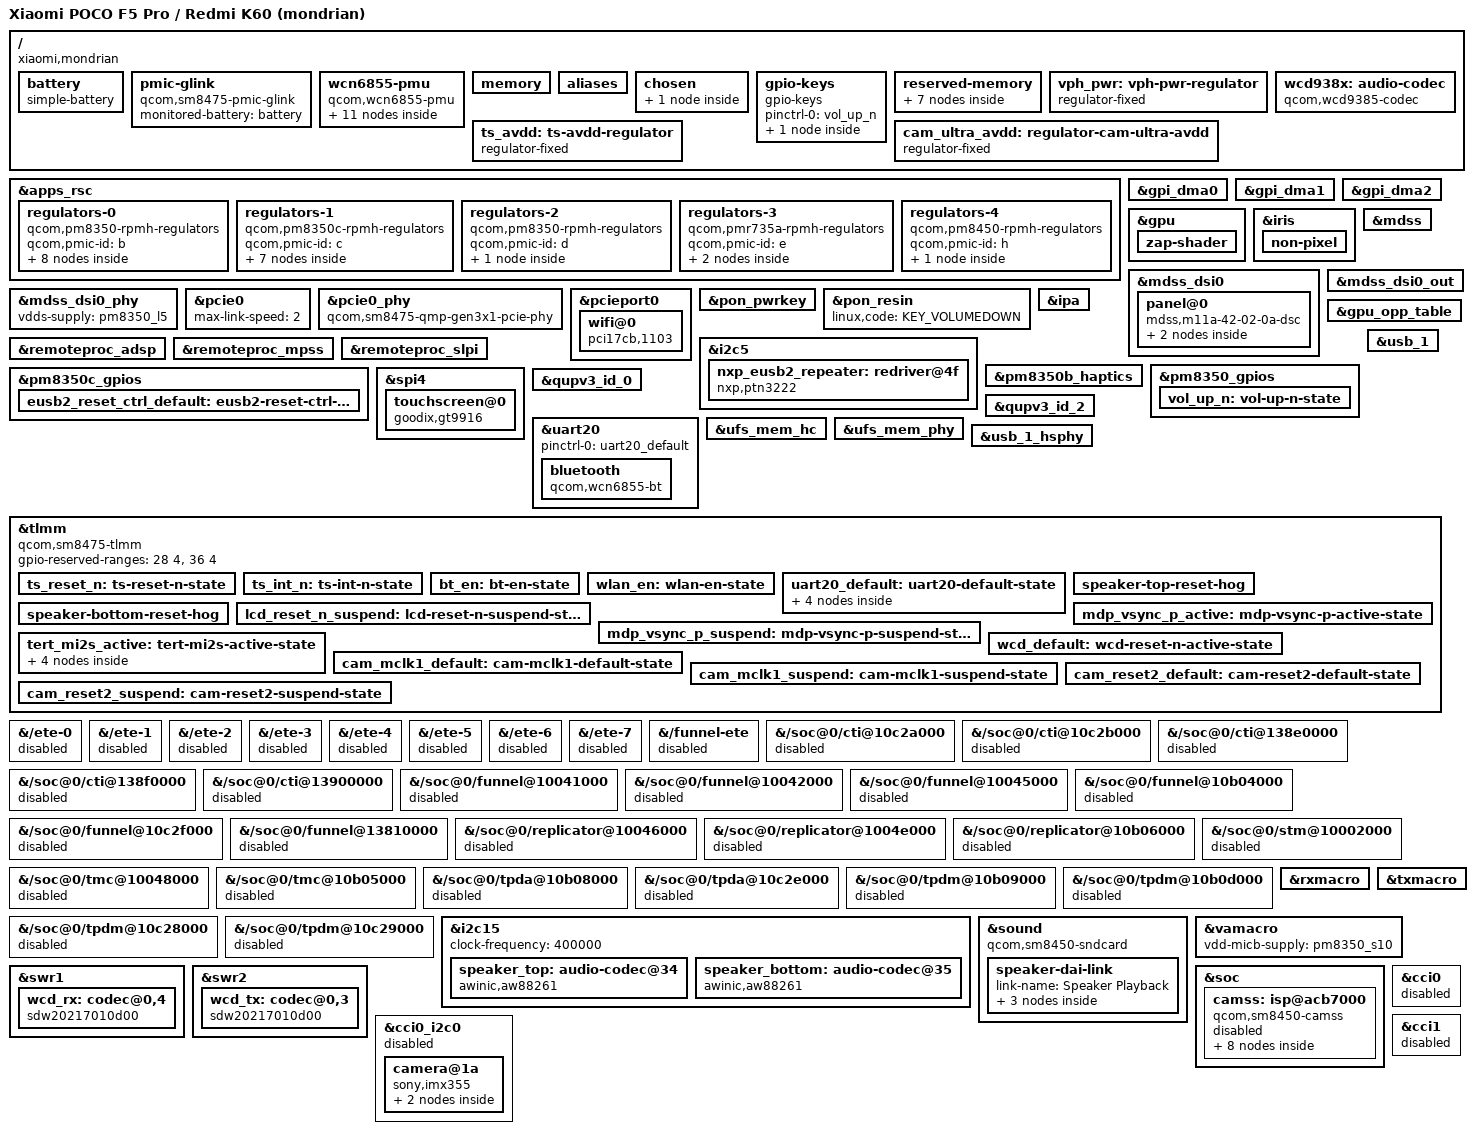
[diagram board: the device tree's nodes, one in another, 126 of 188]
// SPDX-License-Identifier: GPL-2.0-only
/*
 * Xiaomi POCO F5 Pro / Redmi K60 (mondrian), Qualcomm SM8475.
 *
 * Ported onto the marble board port: same SoC, same two aw88261 amps fed by
 * TERTIARY_TDM_RX_0. Device specific values (panel, camera, amp wiring,
 * reserved memory, BT address) come from the earlier mondrian port
 * (commit 3328e356fa13 of the pre-marble tree) and the device's own vendor
 * overlay / vendor DT dump.
 *
 * Firmware is expected under qcom/sm8475/xiaomi/mondrian/.
 */
/dts-v1/;

#include <dt-bindings/arm/qcom,ids.h>
#include <dt-bindings/gpio/gpio.h>
#include <dt-bindings/input/input.h>
#include <dt-bindings/interconnect/qcom,icc.h>
#include <dt-bindings/interconnect/qcom,sm8450.h>
#include <dt-bindings/interrupt-controller/irq.h>
#include <dt-bindings/media/video-interfaces.h>
#include <dt-bindings/pinctrl/qcom,pmic-gpio.h>
#include <dt-bindings/regulator/qcom,rpmh-regulator.h>

#include "sm8475.dtsi"
#include "pm8350.dtsi"
#include "pm8350b.dtsi"
#include "pm8350c.dtsi"
#include "pm8450.dtsi"
#include "pmk8350.dtsi"
#include "pmr735a.dtsi"

/delete-node/ &adsp_mem;
/delete-node/ &rmtfs_mem;
/delete-node/ &xbl_ramdump_mem;
/delete-node/ &xbl_sc_mem;

/ {
	model = "Xiaomi POCO F5 Pro / Redmi K60 (mondrian)";
	compatible = "xiaomi,mondrian", "qcom,sm8475";
	chassis-type = "handset";

	/*
	 * Qualcomm board identification. The stock ABL matches a DTB against
	 * these before it will boot at all; without them a DTB placed in
	 * vendor_boot is rejected and the device drops straight to fastboot.
	 * Values taken from the device's own vendor overlay (fragment@142).
	 */
	qcom,msm-id = <0x213 0x10000>, <0x21c 0x10000>, <0x212 0x10000>;
	qcom,board-id = <0x10008 0x00>;

	/*
	 * Battery/charger run in ADSP firmware (battmgr) over pmic_glink. No
	 * usb-c-connector yet: usb_1_dwc3 stays dr_mode=peripheral for netboot.
	 */
	/*
	 * Carried over from marble: the ADSP does not report a design voltage
	 * and UPower needs one to turn charge into energy. Capacity and design
	 * voltage are unverified for mondrian.
	 */
	battery: battery {
		compatible = "simple-battery";
		charge-full-design-microamp-hours = <5000000>;
		voltage-min-design-microvolt = <3870000>;
	};

	pmic-glink {
		compatible = "qcom,sm8475-pmic-glink", "qcom,sm8450-pmic-glink", "qcom,pmic-glink";
		#address-cells = <1>;
		#size-cells = <0>;
		monitored-battery = <&battery>;
	};

	/* QCA6490 (WCN6855 family, PCI 17cb:1103) wired as on sm8450-hdk */
	wcn6855-pmu {
		compatible = "qcom,wcn6855-pmu";

		/*
		 * mondrian's vendor DT only describes the wlan-en pin here; there
		 * is no xo-clk/ctrl pin, so neither is driven from Linux.
		 */
		pinctrl-0 = <&bt_en>, <&wlan_en>;
		pinctrl-names = "default";

		wlan-enable-gpios = <&tlmm 80 GPIO_ACTIVE_HIGH>;
		bt-enable-gpios = <&tlmm 81 GPIO_ACTIVE_HIGH>;

		/*
		 * Rail mapping from the device's own DT (vendor: vreg_s10b_1p8,
		 * vreg_s2e_0p85, vreg_s11b_0p95, vreg_s12b_1p25, vreg_s1c_1p88).
		 */
		vddio-supply = <&pm8350_s10>;
		vddaon-supply = <&pmr735a_s2>;
		vddpmumx-supply = <&pmr735a_s2>;
		vddpmucx-supply = <&pm8350_s11>;
		vddpmu-supply = <&pm8350_s11>;
		vddrfa0p95-supply = <&pm8350_s11>;
		vddrfa1p3-supply = <&pm8350_s12>;
		vddrfa1p9-supply = <&pm8350c_s1>;
		vddpcie1p3-supply = <&pm8350_s12>;
		vddpcie1p9-supply = <&pm8350c_s1>;

		regulators {
			vreg_pmu_rfa_cmn_0p8: ldo0 {
				regulator-name = "vreg_pmu_rfa_cmn_0p8";
			};

			vreg_pmu_aon_0p8: ldo1 {
				regulator-name = "vreg_pmu_aon_0p8";
			};

			vreg_pmu_wlcx_0p8: ldo2 {
				regulator-name = "vreg_pmu_wlcx_0p8";
			};

			vreg_pmu_wlmx_0p8: ldo3 {
				regulator-name = "vreg_pmu_wlmx_0p8";
			};

			vreg_pmu_btcmx_0p8: ldo4 {
				regulator-name = "vreg_pmu_btcmx_0p8";
			};

			vreg_pmu_pcie_1p8: ldo5 {
				regulator-name = "vreg_pmu_pcie_1p8";
			};

			vreg_pmu_pcie_0p9: ldo6 {
				regulator-name = "vreg_pmu_pcie_0p9";
			};

			vreg_pmu_rfa_0p8: ldo7 {
				regulator-name = "vreg_pmu_rfa_0p8";
			};

			vreg_pmu_rfa_1p2: ldo8 {
				regulator-name = "vreg_pmu_rfa_1p2";
			};

			vreg_pmu_rfa_1p7: ldo9 {
				regulator-name = "vreg_pmu_rfa_1p7";
			};
		};
	};

	/delete-node/ memory@a0000000;

	memory {
		device_type = "memory";
		reg = <0x0 0x80000000 0x0 0x6a000000>,
		      <0x0 0xf4600000 0x0 0x0ba00000>,
		      <0x8 0x00000000 0x0 0x37500000>,
		      <0x9 0x00000000 0x1 0x80000000>,
		      <0x8 0x40000000 0x0 0xc0000000>,
		      <0x8 0x37b00000 0x0 0x01e00000>;
	};

	aliases {
		serial0 = &uart7;
		serial1 = &uart20;
	};

	chosen {
		#address-cells = <2>;
		#size-cells = <2>;
		ranges;

		stdout-path = "serial0:115200n8";

		bootargs = "PMOS_NOSPLASH console=tty0 console=ttyMSM0,115200n8 earlycon loglevel=8 ignore_loglevel printk.devkmsg=on pstore.compress=none log_buf_len=2M msm_geni_serial.con_enabled=0";

		/* Unverified: the mondrian panel is 1440x3200 */
		framebuffer: framebuffer@b8000000 {
			compatible = "simple-framebuffer";
			reg = <0x0 0xb8000000 0x0 0x2b00000>;
			width = <1440>;
			height = <3200>;
			stride = <(1440 * 4)>;
			format = "a8r8g8b8";

			clocks = <&gcc GCC_DISP_HF_AXI_CLK>;
		};
	};

	gpio-keys {
		compatible = "gpio-keys";

		pinctrl-0 = <&vol_up_n>;
		pinctrl-names = "default";

		key-volume-up {
			label = "Volume Up";
			linux,code = <KEY_VOLUMEUP>;
			gpios = <&pm8350_gpios 6 GPIO_ACTIVE_LOW>;
			debounce-interval = <15>;
			wakeup-source;
		};
	};

	reserved-memory {
		/*
		 * Encoder ARP buffers (one 256 KiB slot per session). Handed to
		 * VMID CP_NON_PIXEL by the iris driver, so never mapped by Linux.
		 */
		iris_arp_mem: iris-arp {
			size = <0x0 0x100000>;
			alignment = <0x0 0x40000>;
			no-map;
		};

		xbl_ramdump_mem: memory@a6b80000 {
			reg = <0x0 0xa6b80000 0x0 0x280000>;
			no-map;
		};

		xbl_sc_mem: memory@a6e00000 {
			reg = <0x0 0xa6e00000 0x0 0x40000>;
			no-map;
		};

		adsp_mem: memory@9fd00000 {
			reg = <0x0 0x9fd00000 0x0 0x3100000>;
			no-map;
		};

		ramoops@85200000 {
			compatible = "ramoops";
			reg = <0x0 0x85200000 0x0 0x400000>;
			record-size = <0x100000>;
			console-size = <0x200000>;
			pmsg-size = <0x100000>;
			no-map;
		};

		/* mondrian: rmtfs buffer at 0xf8700000, 2.5 MiB + guard pages */
		rmtfs_mem: memory@f8700000 {
			compatible = "qcom,rmtfs-mem";
			reg = <0x0 0xf8700000 0x0 0x282000>;
			no-map;

			qcom,client-id = <1>;
			qcom,use-guard-pages;
			qcom,vmid = <QCOM_SCM_VMID_MSS_MSA>;
		};

		/*
		 * Bootloader splash / framebuffer. Exposed to simpledrm so the
		 * kernel can take over the display the bootloader already
		 * initialised and print the console to it. no-map is dropped so
		 * the region can be mapped; 1440x3200x4 = 0x1194000 bytes.
		 */
		framebuffer@b8000000 {
			compatible = "simple-framebuffer";
			reg = <0x0 0xb8000000 0x0 0x1194000>;
			width = <1440>;
			height = <3200>;
			stride = <5760>;
			format = "a8r8g8b8";
			status = "okay";
		};
	};

	vph_pwr: vph-pwr-regulator {
		compatible = "regulator-fixed";
		regulator-name = "vph_pwr";
		regulator-min-microvolt = <3700000>;
		regulator-max-microvolt = <3700000>;

		regulator-always-on;
		regulator-boot-on;
	};

	/* Touch AVDD switch on tlmm 71, from the device's own DT (unverified) */
	ts_avdd: ts-avdd-regulator {
		compatible = "regulator-fixed";
		regulator-name = "ts_avdd";
		gpio = <&tlmm 71 GPIO_ACTIVE_HIGH>;
		enable-active-high;
	};

	/*
	 * Ultra-wide camera AVDD on tlmm 6, from the device's vendor overlay
	 * (mondrian dtbo, cam_cci0 fragment). Deliberately not always-on: the
	 * sensor driver is supposed to control it.
	 */
	cam_ultra_avdd: regulator-cam-ultra-avdd {
		compatible = "regulator-fixed";
		regulator-name = "camera_ultra_avdd";
		regulator-min-microvolt = <2800000>;
		regulator-max-microvolt = <2800000>;
		gpio = <&tlmm 6 GPIO_ACTIVE_HIGH>;
		enable-active-high;
	};
};

/ {
	/* Stock wcd938x-codec: reset gpio43, 1.8 V from S10B, micbias 2.75 V from BOB */
	wcd938x: audio-codec {
		compatible = "qcom,wcd9385-codec";

		pinctrl-0 = <&wcd_default>;
		pinctrl-names = "default";

		qcom,micbias1-microvolt = <2750000>;
		qcom,micbias2-microvolt = <2750000>;
		qcom,micbias3-microvolt = <2750000>;
		qcom,micbias4-microvolt = <2750000>;
		qcom,mbhc-buttons-vthreshold-microvolt = <75000 150000 237000 500000 500000 500000 500000 500000>;
		qcom,mbhc-headset-vthreshold-microvolt = <1700000>;
		qcom,mbhc-headphone-vthreshold-microvolt = <50000>;
		qcom,rx-device = <&wcd_rx>;
		qcom,tx-device = <&wcd_tx>;

		reset-gpios = <&tlmm 43 GPIO_ACTIVE_LOW>;

		vdd-buck-supply = <&pm8350_s10>;
		vdd-rxtx-supply = <&pm8350_s10>;
		vdd-io-supply = <&pm8350_s10>;
		vdd-mic-bias-supply = <&pm8350c_bob>;

		#sound-dai-cells = <1>;
	};
};

&apps_rsc {
	regulators-0 {
		compatible = "qcom,pm8350-rpmh-regulators";
		qcom,pmic-id = "b";

		/*
		 * usb/pcie0 phy 0.88 V (stock init 880 mV, sm8450-hdk 880-888 mV);
		 * at the old 720 mV floor the pcie0 qmp phy timed out on init.
		 */
		pm8350_l5: ldo5 {
			regulator-name = "pm8350_l5";
			regulator-min-microvolt = <880000>;
			regulator-max-microvolt = <888000>;
			regulator-initial-mode = <RPMH_REGULATOR_MODE_HPM>;
		};

		pm8350_s10: smps10 {
			regulator-name = "pm8350_s10";
			regulator-min-microvolt = <1800000>;
			regulator-max-microvolt = <1800000>;
		};

		pm8350_l2: ldo2 {
			regulator-name = "pm8350_l2";
			regulator-min-microvolt = <2700000>;
			regulator-max-microvolt = <3300000>;
			regulator-initial-mode = <RPMH_REGULATOR_MODE_HPM>;
		};

		pm8350_l6: ldo6 {
			regulator-name = "pm8350_l6";
			regulator-min-microvolt = <1200000>;
			regulator-max-microvolt = <1216000>;
			regulator-initial-mode = <RPMH_REGULATOR_MODE_HPM>;
		};

		pm8350_l7: ldo7 {
			regulator-name = "pm8350_l7";
			regulator-min-microvolt = <2400000>;
			regulator-max-microvolt = <3544000>;
			regulator-initial-mode = <RPMH_REGULATOR_MODE_HPM>;
		};

		pm8350_l9: ldo9 {
			regulator-name = "pm8350_l9";
			regulator-min-microvolt = <1200000>;
			regulator-max-microvolt = <1304000>;
			regulator-initial-mode = <RPMH_REGULATOR_MODE_HPM>;
		};

		/* QCA6490 rails, same as sm8450-hdk (stock cnss vdd-wlan-dig/-rfa2) */
		pm8350_s11: smps11 {
			regulator-name = "pm8350_s11";
			regulator-min-microvolt = <966000>;
			regulator-max-microvolt = <1104000>;
		};

		pm8350_s12: smps12 {
			regulator-name = "pm8350_s12";
			regulator-min-microvolt = <1350000>;
			regulator-max-microvolt = <1400000>;
		};
	};

	regulators-1 {
		compatible = "qcom,pm8350c-rpmh-regulators";
		qcom,pmic-id = "c";

		/* WCD9385 micbias supply (stock cdc-vdd-mic-bias) */
		pm8350c_bob: bob {
			regulator-name = "pm8350c_bob";
			regulator-min-microvolt = <3008000>;
			regulator-max-microvolt = <3960000>;
			regulator-initial-mode = <RPMH_REGULATOR_MODE_AUTO>;
		};

		/* QCA6490 vddrfa1p9 / vddpcie1p9 (stock vdd-wlan-rfa1) */
		pm8350c_s1: smps1 {
			regulator-name = "pm8350c_s1";
			regulator-min-microvolt = <1800000>;
			regulator-max-microvolt = <2024000>;
		};

		/* touch vddio: stock 1.8 V fixed */
		pm8350c_l2: ldo2 {
			regulator-name = "pm8350c_l2";
			regulator-min-microvolt = <1800000>;
			regulator-max-microvolt = <1800000>;
			regulator-initial-mode = <RPMH_REGULATOR_MODE_HPM>;
		};

		/* touch avdd: stock 3.224 V fixed */
		pm8350c_l9: ldo9 {
			regulator-name = "pm8350c_l9";
			regulator-min-microvolt = <3224000>;
			regulator-max-microvolt = <3224000>;
			regulator-initial-mode = <RPMH_REGULATOR_MODE_HPM>;
		};

		pm8350c_l10: ldo10 {
			regulator-name = "pm8350c_l10";
			regulator-min-microvolt = <1200000>;
			regulator-max-microvolt = <1304000>;
			regulator-initial-mode = <RPMH_REGULATOR_MODE_HPM>;
		};

		/* panel vddio: stock 1.8 V */
		pm8350c_l12: ldo12 {
			regulator-name = "pm8350c_l12";
			regulator-min-microvolt = <1800000>;
			regulator-max-microvolt = <1800000>;
			regulator-initial-mode = <RPMH_REGULATOR_MODE_HPM>;
		};

		/* panel vci: stock 3.0 V */
		pm8350c_l13: ldo13 {
			regulator-name = "pm8350c_l13";
			regulator-min-microvolt = <3000000>;
			regulator-max-microvolt = <3000000>;
			regulator-initial-mode = <RPMH_REGULATOR_MODE_HPM>;
		};
	};

	/*
	 * PM8350B LDOs (stock rpmh resource "ldod1"). No pm8350b table in
	 * mainline; the resource name is built from pmic-id + ldoN, and L1
	 * is an NLDO like pm8350's, so reuse that table.
	 */
	regulators-2 {
		compatible = "qcom,pm8350-rpmh-regulators";
		qcom,pmic-id = "d";

		/* panel vddd: stock 1.2 V */
		pm8350b_l1: ldo1 {
			regulator-name = "pm8350b_l1";
			regulator-min-microvolt = <1200000>;
			regulator-max-microvolt = <1200000>;
			regulator-initial-mode = <RPMH_REGULATOR_MODE_HPM>;
		};
	};

	regulators-3 {
		compatible = "qcom,pmr735a-rpmh-regulators";
		qcom,pmic-id = "e";

		/* QCA6490 vddpmumx (stock vdd-wlan-aon) */
		pmr735a_s2: smps2 {
			regulator-name = "pmr735a_s2";
			regulator-min-microvolt = <500000>;
			regulator-max-microvolt = <1040000>;
		};

		/* WLAN antenna switch (stock wlan-ant-switch-supply, 2.8 V) */
		pmr735a_l7: ldo7 {
			regulator-name = "pmr735a_l7";
			regulator-min-microvolt = <2800000>;
			regulator-max-microvolt = <2800000>;
			regulator-initial-mode = <RPMH_REGULATOR_MODE_HPM>;
			regulator-always-on;
		};
	};

	regulators-4 {
		compatible = "qcom,pm8450-rpmh-regulators";
		qcom,pmic-id = "h";

		pm8450_l4: ldo4 {
			regulator-name = "pm8450_l4";
			regulator-min-microvolt = <1800000>;
			regulator-max-microvolt = <1800000>;
			regulator-initial-mode = <RPMH_REGULATOR_MODE_HPM>;
		};
	};
};

&gpi_dma0 {
	/*
	 * iommus kept from sm8450.dtsi (SID 0x5b6, matches live stock): with
	 * ARM_SMMU_DISABLE_BYPASS_BY_DEFAULT=y, deleting it would fault the
	 * touch SPI / i2c5 GPI DMA instead of bypassing.
	 */
	status = "okay";
};

&gpi_dma1 {
	status = "okay";

	/delete-property/ iommus;
};

&gpi_dma2 {
	status = "okay";

	/delete-property/ iommus;
};

&gpu {
	/*
	 * Adreno 730v3 (stock qcom,chipid 0x07030002, sold as "725"). Firmware
	 * from stock /vendor/firmware: a730_sqe.fw + gmu_gen70000.bin in
	 * qcom/, the Xiaomi-signed zap below. Same setup as sm8475-nothing-pong.
	 */
	status = "okay";

	zap-shader {
		firmware-name = "qcom/sm8475/xiaomi/mondrian/a730_zap.mbn";
	};
};

&iris {
	status = "okay";

	/*
	 * VPU2 reads the encoder ARP buffer through the secure non-pixel stream
	 * ID, which the hypervisor walks with VMID CP_NON_PIXEL's stage 2 (stock:
	 * secure_non_pixel_cb, ARP at IOVA 0x257c0000). It must not share a
	 * context bank with the HLOS stream IDs, so give it its own device.
	 */
	non-pixel {
		iommus = <&apps_smmu 0x2184 0x400>;
		memory-region = <&iris_arp_mem>;
		qcom,iommu-vmid = <0xb>; /* QCOM_SCM_VMID_CP_NON_PIXEL */
	};
};

&mdss {
	status = "okay";
};

/*
 * Panel: M11A 42-02-0A (M11A42, DSC). DSI0 port 1 (mdss_dsi0_out) feeds the
 * panel input endpoint. Rail mapping from the device's own DT: vdda =
 * vreg_l6b_1p2, panel vdd = vreg_l13c_3p0, vddio = vreg_l12c_1p8, reset on
 * tlmm 0. NOTE: the mdss,m11a-42-02-0a-dsc driver is not in this tree yet.
 */
&mdss_dsi0 {
	vdda-supply = <&pm8350_l6>;
	vddio-supply = <&pm8350c_l12>;
	status = "okay";

	panel@0 {
		compatible = "mdss,m11a-42-02-0a-dsc";
		reg = <0>;

		/* stock: qcom,platform-reset-gpio = <&tlmm 0 0> */
		reset-gpios = <&tlmm 0 GPIO_ACTIVE_LOW>;

		vdd-supply = <&pm8350c_l13>;
		vddio-supply = <&pm8350c_l12>;

		pinctrl-0 = <&mdp_vsync_p_active>;
		pinctrl-1 = <&lcd_reset_n_suspend>, <&mdp_vsync_p_suspend>;
		pinctrl-names = "default", "sleep";

		port {
			panel_in: endpoint {
				remote-endpoint = <&mdss_dsi0_out>;
			};
		};
	};
};

&mdss_dsi0_out {
	data-lanes = <0 1 2 3>;
	remote-endpoint = <&panel_in>;
};

&mdss_dsi0_phy {
	vdds-supply = <&pm8350_l5>;
	status = "okay";
};

&pcie0 {
	max-link-speed = <2>;
	status = "okay";
};

&pcie0_phy {
	/*
	 * cape pcie0 phy is QSERDES V6 (stock qcom,phy-sequence), not the
	 * sm8450 V5 one. Stock supplies: vreg-0p9 = pm8350_l5 (0.88 V),
	 * vreg-1p8 = pm8350c_l10 (1.2 V).
	 */
	compatible = "qcom,sm8475-qmp-gen3x1-pcie-phy";
	vdda-phy-supply = <&pm8350_l5>;
	vdda-pll-supply = <&pm8350c_l10>;
	status = "okay";
};

&pcieport0 {
	wifi@0 {
		compatible = "pci17cb,1103";
		reg = <0x10000 0x0 0x0 0x0 0x0>;

		vddrfacmn-supply = <&vreg_pmu_rfa_cmn_0p8>;
		vddaon-supply = <&vreg_pmu_aon_0p8>;
		vddwlcx-supply = <&vreg_pmu_wlcx_0p8>;
		vddwlmx-supply = <&vreg_pmu_wlmx_0p8>;
		vddpcie1p8-supply = <&vreg_pmu_pcie_1p8>;
		vddpcie0p9-supply = <&vreg_pmu_pcie_0p9>;
		vddrfa0p8-supply = <&vreg_pmu_rfa_0p8>;
		vddrfa1p2-supply = <&vreg_pmu_rfa_1p2>;
		vddrfa1p8-supply = <&vreg_pmu_rfa_1p7>;
	};
};

&pon_pwrkey {
	status = "okay";
};

&pon_resin {
	linux,code = <KEY_VOLUMEDOWN>;
	status = "okay";
};

/*
 * Stock (qcom,gpu-pwrlevels) runs this A730v3 at 220..580 MHz only; the
 * inherited SM8475 table goes to 900 MHz at TURBO_L1, above this bin.
 */
&gpu_opp_table {
	/*
	 * Keep only the stock levels 220/285/324/364/439/515/580 MHz. The merged
	 * sm8450+sm8475 table had 18 OPPs, more than the GMU's 16 slots.
	 */
	/delete-node/ opp-900000000;
	/delete-node/ opp-862000000;
	/delete-node/ opp-815000000;
	/delete-node/ opp-765000000;
	/delete-node/ opp-710000000;
	/delete-node/ opp-645000000;
	/delete-node/ opp-818000000;
	/delete-node/ opp-791000000;
	/delete-node/ opp-734000000;
	/delete-node/ opp-640000000;
	/delete-node/ opp-599000000;
	/delete-node/ opp-545000000;
	/delete-node/ opp-492000000;
	/delete-node/ opp-421000000;
	/delete-node/ opp-350000000;
	/delete-node/ opp-317000000;
};

&remoteproc_adsp {
	firmware-name = "qcom/sm8475/xiaomi/mondrian/adsp.mdt";
	status = "okay";
};

&ipa {
	qcom,gsi-loader = "self";
	memory-region = <&ipa_fw_mem>;
	firmware-name = "qcom/sm8475/xiaomi/mondrian/ipa_fws.mdt";
	status = "okay";
};

&remoteproc_mpss {
	firmware-name = "qcom/sm8475/xiaomi/mondrian/modem.mdt";
	status = "okay";
};

&remoteproc_slpi {
	firmware-name = "qcom/sm8475/xiaomi/mondrian/slpi2.mdt";
	status = "okay";
};

&i2c5 {
	/*
	 * i2c5's base pinctrl-0 (qup_i2c5_data_clk) lives under &tlmm, which is
	 * disabled; with CONFIG_MODULES=y pinctrl core then returns -EPROBE_DEFER
	 * forever, so the bus (and the eUSB2 repeater on it) never probes. Rely on
	 * the bootloader mux (stock: gpio206/207 = qup5) instead.
	 */
	/delete-property/ pinctrl-names;
	/delete-property/ pinctrl-0;
	clock-frequency = <100000>;
	/delete-property/ interconnects;
	/delete-property/ interconnect-names;
	qcom,shared;
	status = "okay";

	/*
	 * PHONE_DUMP.md (2026-09-24): stock uses downstream compatible
	 * "nxp,eusb2-repeater" (no mainline driver). Mainline driver for
	 * this exact chip is "nxp,ptn3222" (drivers/phy/phy-nxp-ptn3222.c,
	 * CONFIG_PHY_NXP_PTN3222=m). Without this, usb_1_hsphy's
	 * "phys = <&nxp_eusb2_repeater>;" never resolves to a probed phy
	 * provider, so it defers forever ("failed to get repeater").
	 */
	nxp_eusb2_repeater: redriver@4f {
		compatible = "nxp,ptn3222";
		reg = <0x4f>;
		#phy-cells = <0>;
		vdd1v8-supply = <&pm8350_s10>;
		vdd3v3-supply = <&pm8350_l2>;
		reset-gpios = <&pm8350c_gpios 7 GPIO_ACTIVE_LOW>;
		pinctrl-names = "default";
		pinctrl-0 = <&eusb2_reset_ctrl_default>;
	};

	/*
	 * No PM8008 on mondrian: the vendor DT has none, and the i-PMIC reset
	 * line would collide with cam_ultra_avdd on tlmm 6.
	 */
};

&pm8350b_haptics {
	qcom,vmax-microvolt = <1450000>;
	qcom,lra-period-us = <5882>;
	status = "okay";
};

&pm8350c_gpios {
	eusb2_reset_ctrl_default: eusb2-reset-ctrl-default-state {
		pins = "gpio7";
		function = PMIC_GPIO_FUNC_NORMAL;
		input-enable;
		output-enable;
		bias-disable;
		power-source = <1>;
		qcom,drive-strength = <PMIC_GPIO_STRENGTH_MED>;
	};
};

&pm8350_gpios {
	vol_up_n: vol-up-n-state {
		pins = "gpio6";
		function = PMIC_GPIO_FUNC_NORMAL;
		input-enable;
		bias-pull-up;
		power-source = <1>;
	};
};

&spi4 {
	status = "okay";

	touchscreen@0 {
		compatible = "goodix,gt9916";
		reg = <0>;

		interrupt-parent = <&tlmm>;
		interrupts = <21 IRQ_TYPE_LEVEL_LOW>;
		reset-gpios = <&tlmm 20 GPIO_ACTIVE_LOW>;

		avdd-supply = <&ts_avdd>;
		vddio-supply = <&pm8350c_l2>;

		spi-max-frequency = <15000000>;

		/* 1440x3200 panel, reported in the same 10x units as on marble */
		touchscreen-size-x = <14400>;
		touchscreen-size-y = <32000>;

		pinctrl-names = "default";
		pinctrl-0 = <&ts_int_n>, <&ts_reset_n>;
	};
};

/*
 * PHONE_DUMP.md (2026-09-24): the /delete-property/ iommus below (on
 * qupv3_id_0, ufs_mem_hc, usb_1_dwc3) was backwards. Kernel config has
 * CONFIG_ARM_SMMU_DISABLE_BYPASS_BY_DEFAULT=y, so a DMA-capable device
 * with NO iommus entry matches no SMR when arm-smmu resets and gets
 * FAULTED, not bypassed. Restored to the base sm8450.dtsi/sm8475.dtsi
 * values (stock confirms UFS's stream ID 0xe0 is correct).
 */
&qupv3_id_0 {
	status = "okay";
};

&qupv3_id_2 {
	status = "okay";
};

&uart20 {
	/* stock bt_qca6490 hs-uart @0x894000, wired as on sm8450-hdk */
	pinctrl-0 = <&uart20_default>;
	pinctrl-names = "default";
	status = "okay";

	bluetooth {
		compatible = "qcom,wcn6855-bt";

		/*
		 * The factory BD_ADDR lives on the Android vendor partition,
		 * which the postmarketOS install replaces. Without a non-zero
		 * address the controller is closed during init and BlueZ never
		 * sees it. Stable, locally administered address.
		 */
		local-bd-address = [c2 6f 1b b1 3d 99];

		vddrfacmn-supply = <&vreg_pmu_rfa_cmn_0p8>;
		vddaon-supply = <&vreg_pmu_aon_0p8>;
		vddwlcx-supply = <&vreg_pmu_wlcx_0p8>;
		vddwlmx-supply = <&vreg_pmu_wlmx_0p8>;
		vddbtcmx-supply = <&vreg_pmu_btcmx_0p8>;
		vddrfa0p8-supply = <&vreg_pmu_rfa_0p8>;
		vddrfa1p2-supply = <&vreg_pmu_rfa_1p2>;
		vddrfa1p8-supply = <&vreg_pmu_rfa_1p7>;

		max-speed = <3200000>;
	};
};

&ufs_mem_hc {
	status = "okay";

	/* reset-gpios (tlmm 210) omitted: tlmm is disabled, so it would defer ufshc forever */

	vcc-supply = <&pm8350_l7>;
	vcc-max-microamp = <1100000>;
	vccq-supply = <&pm8350_l9>;
	vccq-max-microamp = <1200000>;
};

&ufs_mem_phy {
	status = "okay";

	vdda-phy-supply = <&pm8350_l5>;
	vdda-pll-supply = <&pm8350c_l10>;
};

&usb_1 {
	/delete-property/ interconnects;
	/delete-property/ interconnect-names;

	qcom,select-utmi-as-pipe-clk;

	/* v7.x: dwc3 core is flattened into the qcom glue node */
	dr_mode = "peripheral";
	maximum-speed = "high-speed";
	phys = <&usb_1_hsphy>;
	phy-names = "usb2-phy";

	status = "okay";
};

&usb_1_hsphy {
	status = "okay";

	vdd-supply = <&pm8350_l5>;
	vdda12-supply = <&pm8350c_l10>;
	phys = <&nxp_eusb2_repeater>;
};

&tlmm {
	/*
	 * 2026-09-25: TLMM is readable from Linux (devmem over the USB shell:
	 * gpio16 ctl @0xf110000 = 0x1, i2c5 pins gpio206/207 = 0x1807/qup5),
	 * so the earlier "TrustZone blocks TLMM" theory was wrong. The two
	 * old crashes were almost certainly gpiolib reading the secure-owned
	 * pins when the gpiochip registered: stock marks 28-31 and 36-39 as
	 * qcom,gpios-reserved, and every mainline sm8450 phone DT carries the
	 * matching gpio-reserved-ranges, which this DT never had.
	 * Register layout checked: base 0xf100000 + 0x1000*id matches the
	 * downstream cape driver (0xf000000 + 0x100000 + 0x1000*id).
	 */
	compatible = "qcom,sm8475-tlmm";
	/*
	 * 28-31 are secure everywhere on this SoC family, and 36-39 crash
	 * gpiolib on registration (see marble). The vendor DT for mondrian only
	 * lists 28-31, but reserving 36-39 as well is harmless.
	 */
	gpio-reserved-ranges = <28 4>, <36 4>;

	ts_reset_n: ts-reset-n-state {
		pins = "gpio20";
		function = "gpio";
		drive-strength = <8>;
		bias-pull-up;
	};

	ts_int_n: ts-int-n-state {
		pins = "gpio21";
		function = "gpio";
		drive-strength = <8>;
		bias-pull-up;
	};

	bt_en: bt-en-state {
		pins = "gpio81";
		function = "gpio";
		drive-strength = <16>;
		output-low;
		bias-pull-down;
	};

	wlan_en: wlan-en-state {
		pins = "gpio80";
		function = "gpio";
		drive-strength = <16>;
		output-low;
		bias-pull-down;
	};

	uart20_default: uart20-default-state {
		cts-pins {
			pins = "gpio76";
			function = "qup20";
			bias-disable;
		};

		rts-pins {
			pins = "gpio77";
			function = "qup20";
			bias-disable;
		};

		rx-pins {
			pins = "gpio78";
			function = "qup20";
			bias-disable;
		};

		tx-pins {
			pins = "gpio79";
			function = "qup20";
			bias-disable;
		};
	};
};

/*
 * v7.x sm8450.dtsi enables CoreSight/QDSS trace. Unused here, and the debug
 * blocks may be locked by TZ on retail devices (reads can hang the SoC),
 * so keep them off.
 */
&{/ete-0} {
	status = "disabled";
};

&{/ete-1} {
	status = "disabled";
};

&{/ete-2} {
	status = "disabled";
};

&{/ete-3} {
	status = "disabled";
};

&{/ete-4} {
	status = "disabled";
};

&{/ete-5} {
	status = "disabled";
};

&{/ete-6} {
	status = "disabled";
};

&{/ete-7} {
	status = "disabled";
};

&{/funnel-ete} {
	status = "disabled";
};

&{/soc@0/cti@10c2a000} {
	status = "disabled";
};

&{/soc@0/cti@10c2b000} {
	status = "disabled";
};

&{/soc@0/cti@138e0000} {
	status = "disabled";
};

&{/soc@0/cti@138f0000} {
	status = "disabled";
};

&{/soc@0/cti@13900000} {
	status = "disabled";
};

&{/soc@0/funnel@10041000} {
	status = "disabled";
};

&{/soc@0/funnel@10042000} {
	status = "disabled";
};

&{/soc@0/funnel@10045000} {
	status = "disabled";
};

&{/soc@0/funnel@10b04000} {
	status = "disabled";
};

&{/soc@0/funnel@10c2f000} {
	status = "disabled";
};

&{/soc@0/funnel@13810000} {
	status = "disabled";
};

&{/soc@0/replicator@10046000} {
	status = "disabled";
};

&{/soc@0/replicator@1004e000} {
	status = "disabled";
};

&{/soc@0/replicator@10b06000} {
	status = "disabled";
};

&{/soc@0/stm@10002000} {
	status = "disabled";
};

&{/soc@0/tmc@10048000} {
	status = "disabled";
};

&{/soc@0/tmc@10b05000} {
	status = "disabled";
};

&{/soc@0/tpda@10b08000} {
	status = "disabled";
};

&{/soc@0/tpda@10c2e000} {
	status = "disabled";
};

&{/soc@0/tpdm@10b09000} {
	status = "disabled";
};

&{/soc@0/tpdm@10b0d000} {
	status = "disabled";
};

&{/soc@0/tpdm@10c28000} {
	status = "disabled";
};

&{/soc@0/tpdm@10c29000} {
	status = "disabled";
};

/*
 * Speakers: 2x Awinic AW88263S (register compatible with AW88261) on i2c15,
 * fed by the tertiary TDM interface ("TDM-LPAIF-RX-TERTIARY"), the same way
 * as on marble. 0x34 = top (also the earpiece, see gpio 52), 0x35 = bottom.
 * Reset lines come from the vendor overlay. The ACF is still loaded, but the
 * TDM rate/slot layout is programmed by the driver from the dai-link (no
 * awinic,keep-fw-i2s-config), so the amps follow the 96 kHz / 4 x 32-bit BE.
 */
&i2c15 {
	clock-frequency = <400000>;
	status = "okay";

	speaker_top: audio-codec@34 {
		compatible = "awinic,aw88261";
		reg = <0x34>;
		#sound-dai-cells = <0>;
		awinic,audio-channel = <0>;
		awinic,sync-flag;
		firmware-name = "aw882xx_acf.bin";
		sound-name-prefix = "Top Speaker";
	};

	speaker_bottom: audio-codec@35 {
		compatible = "awinic,aw88261";
		reg = <0x35>;
		#sound-dai-cells = <0>;
		awinic,audio-channel = <1>;
		awinic,sync-flag;
		firmware-name = "aw882xx_acf.bin";
		sound-name-prefix = "Bottom Speaker";
	};
};

&tlmm {
	/*
	 * The aw88261 driver in this tree does not consume reset-gpios yet, so
	 * hold both amps out of reset the same way marble does. The vendor reset
	 * lines are active low in practice (high = running).
	 */
	speaker-top-reset-hog {
		gpio-hog;
		gpios = <1 GPIO_ACTIVE_HIGH>;
		output-high;
		line-name = "speaker-top-reset-n";
	};

	speaker-bottom-reset-hog {
		gpio-hog;
		gpios = <3 GPIO_ACTIVE_HIGH>;
		output-high;
		line-name = "speaker-bottom-reset-n";
	};

	/* MDSS vsync and panel-reset sleep states, from stock */
	lcd_reset_n_suspend: lcd-reset-n-suspend-state {
		pins = "gpio0";
		function = "gpio";
		drive-strength = <2>;
		bias-pull-down;
	};

	mdp_vsync_p_active: mdp-vsync-p-active-state {
		pins = "gpio86";
		function = "mdp_vsync";
		drive-strength = <2>;
		bias-pull-down;
	};

	mdp_vsync_p_suspend: mdp-vsync-p-suspend-state {
		pins = "gpio86";
		function = "mdp_vsync";
		drive-strength = <2>;
		bias-pull-down;
	};

	tert_mi2s_active: tert-mi2s-active-state {
		sck-pins {
			pins = "gpio121";
			function = "mi2s2_sck";
			drive-strength = <8>;
			bias-disable;
			output-low;
		};

		data0-pins {
			pins = "gpio122";
			function = "mi2s2_data0";
			drive-strength = <8>;
			bias-disable;
		};

		ws-pins {
			pins = "gpio123";
			function = "mi2s2_ws";
			drive-strength = <8>;
			bias-disable;
			output-low;
		};

		data1-pins {
			pins = "gpio124";
			function = "mi2s2_data1";
			drive-strength = <8>;
			bias-pull-down;
		};
	};
};

&sound {
	compatible = "qcom,sm8450-sndcard";
	/*
	 * Must match the installed topology firmware name: the kernel loads
	 * qcom/<driver_name>/<card->name>-tplg.bin, and the package installs
	 * qcom/sm8450/Xiaomi-Mondrian-tplg.bin (driver_name is "sm8450").
	 */
	model = "Xiaomi-Mondrian";
	speaker-earpiece-gpios = <&tlmm 52 GPIO_ACTIVE_HIGH>;

	pinctrl-0 = <&tert_mi2s_active>;
	pinctrl-names = "default";

	/* Stock: qcom,mi2s-tdm-is-hw-vote-needed for the tertiary interface */
	clocks = <&q6prmcc LPASS_HW_MACRO_VOTE LPASS_CLK_ATTRIBUTE_COUPLE_NO>,
		 <&q6prmcc LPASS_CLK_ID_TER_TDM_IBIT LPASS_CLK_ATTRIBUTE_COUPLE_NO>;
	clock-names = "tdm-vote", "tdm-bclk";

	/* Stock speaker TDM: 96 kHz, 4 x 32-bit slots, short frame sync */
	qcom,tdm-slots = <4>;
	qcom,tdm-slot-width = <32>;
	qcom,tdm-rate = <48000>;
	qcom,tdm-format = "dsp_a";

	/*
	 * Only the TDM speaker path is wired up. The WCD9385 capture dai-link
	 * and its audio-routing entries are deliberately left out: the codec is
	 * unconfirmed on mondrian, and a component or DAPM widget that never
	 * registers takes the whole card - speaker included - down with it.
	 * The codec, macro and SoundWire nodes below are kept so that capture
	 * can be added once the hardware is confirmed.
	 */
	speaker-dai-link {
		link-name = "Speaker Playback";

		cpu {
			sound-dai = <&q6apmbedai TERTIARY_TDM_RX_0>;
		};

		codec {
			sound-dai = <&speaker_top>, <&speaker_bottom>;
			dai-tdm-slot-num = <4>;
			dai-tdm-slot-width = <32>;
			dai-tdm-slot-rx-mask = <1 1>;
		};

		platform {
			sound-dai = <&q6apm>;
		};
	};
};

&rxmacro {
	status = "okay";
};

&txmacro {
	status = "okay";
};

/* The vendor overlay describes no DMICs; VA macro only provides fsgen */
&vamacro {
	vdd-micb-supply = <&pm8350_s10>;

	status = "okay";
};

&swr1 {
	status = "okay";

	wcd_rx: codec@0,4 {
		compatible = "sdw20217010d00";
		reg = <0 4>;
		qcom,rx-port-mapping = <1 2 3 4 5>;
	};
};

&swr2 {
	status = "okay";

	wcd_tx: codec@0,3 {
		compatible = "sdw20217010d00";
		reg = <0 3>;
		qcom,tx-port-mapping = <1 1 2 3>;
	};
};

&tlmm {
	wcd_default: wcd-reset-n-active-state {
		pins = "gpio43";
		function = "gpio";
		drive-strength = <16>;
		bias-disable;
		output-low;
	};

	cam_mclk1_default: cam-mclk1-default-state {
		pins = "gpio101";
		function = "cam_mclk";
		drive-strength = <4>;
		bias-disable;
	};

	cam_mclk1_suspend: cam-mclk1-suspend-state {
		pins = "gpio101";
		function = "cam_mclk";
		drive-strength = <4>;
		bias-pull-down;
	};

	cam_reset2_default: cam-reset2-default-state {
		pins = "gpio24";
		function = "gpio";
		drive-strength = <2>;
		bias-disable;
		output-high;
	};

	cam_reset2_suspend: cam-reset2-suspend-state {
		pins = "gpio24";
		function = "gpio";
		drive-strength = <2>;
		bias-pull-down;
		output-low;
	};
};

&soc {
	/*
	 * The marble base sm8450.dtsi carries no CAMSS node (SM8450 support is
	 * not in this tree's camss driver yet), so the SoC description is kept
	 * here for the IMX355/CSIPHY1 wiring below. Move it back into sm8450.dtsi
	 * once CAMSS_8450 is merged.
	 */
	camss: isp@acb7000 {
		compatible = "qcom,sm8450-camss";

		reg = <0x0 0x0acb7000 0x0 0x0d00>,
		      <0x0 0x0acb9000 0x0 0x0d00>,
		      <0x0 0x0acbb000 0x0 0x0d00>,
		      <0x0 0x0acc6000 0x0 0x0a00>,
		      <0x0 0x0acca000 0x0 0x0a00>,
		      <0x0 0x0acb6000 0x0 0x1000>,
		      <0x0 0x0ace4000 0x0 0x2000>,
		      <0x0 0x0ace6000 0x0 0x2000>,
		      <0x0 0x0ace8000 0x0 0x2000>,
		      <0x0 0x0acea000 0x0 0x2000>,
		      <0x0 0x0acec000 0x0 0x2000>,
		      <0x0 0x0acee000 0x0 0x2000>,
		      <0x0 0x0ac62000 0x0 0xf000>,
		      <0x0 0x0ac71000 0x0 0xf000>,
		      <0x0 0x0ac80000 0x0 0xf000>,
		      <0x0 0x0acc6000 0x0 0x2800>,
		      <0x0 0x0acca000 0x0 0x2800>;
		reg-names = "csid0",
			    "csid1",
			    "csid2",
			    "csid_lite0",
			    "csid_lite1",
			    "csid_wrapper",
			    "csiphy0",
			    "csiphy1",
			    "csiphy2",
			    "csiphy3",
			    "csiphy4",
			    "csiphy5",
			    "vfe0",
			    "vfe1",
			    "vfe2",
			    "vfe_lite0",
			    "vfe_lite1";

		clocks = <&gcc GCC_CAMERA_HF_AXI_CLK>,
			 <&gcc GCC_CAMERA_SF_AXI_CLK>,
			 <&camcc CAM_CC_CAMNOC_AXI_CLK>,
			 <&camcc CAM_CC_CPAS_AHB_CLK>,
			 <&camcc CAM_CC_CPAS_FAST_AHB_CLK>,
			 <&camcc CAM_CC_CPAS_IFE_0_CLK>,
			 <&camcc CAM_CC_CPAS_IFE_1_CLK>,
			 <&camcc CAM_CC_CPAS_IFE_2_CLK>,
			 <&camcc CAM_CC_CPAS_IFE_LITE_CLK>,
			 <&camcc CAM_CC_CSID_CSIPHY_RX_CLK>,
			 <&camcc CAM_CC_CSIPHY0_CLK>,
			 <&camcc CAM_CC_CSI0PHYTIMER_CLK>,
			 <&camcc CAM_CC_CSIPHY1_CLK>,
			 <&camcc CAM_CC_CSI1PHYTIMER_CLK>,
			 <&camcc CAM_CC_CSIPHY2_CLK>,
			 <&camcc CAM_CC_CSI2PHYTIMER_CLK>,
			 <&camcc CAM_CC_CSIPHY3_CLK>,
			 <&camcc CAM_CC_CSI3PHYTIMER_CLK>,
			 <&camcc CAM_CC_CSIPHY4_CLK>,
			 <&camcc CAM_CC_CSI4PHYTIMER_CLK>,
			 <&camcc CAM_CC_CSIPHY5_CLK>,
			 <&camcc CAM_CC_CSI5PHYTIMER_CLK>,
			 <&camcc CAM_CC_IFE_0_CLK>,
			 <&camcc CAM_CC_IFE_0_FAST_AHB_CLK>,
			 <&camcc CAM_CC_IFE_1_CLK>,
			 <&camcc CAM_CC_IFE_1_FAST_AHB_CLK>,
			 <&camcc CAM_CC_IFE_2_CLK>,
			 <&camcc CAM_CC_IFE_2_FAST_AHB_CLK>,
			 <&camcc CAM_CC_IFE_LITE_CLK>,
			 <&camcc CAM_CC_IFE_LITE_AHB_CLK>,
			 <&camcc CAM_CC_IFE_LITE_CPHY_RX_CLK>,
			 <&camcc CAM_CC_IFE_LITE_CSID_CLK>;
		clock-names = "gcc_axi_hf",
			      "gcc_axi_sf",
			      "camnoc_axi",
			      "cpas_ahb",
			      "cpas_fast_ahb_clk",
			      "cpas_vfe0",
			      "cpas_vfe1",
			      "cpas_vfe2",
			      "cpas_vfe_lite",
			      "csiphy_rx",
			      "csiphy0",
			      "csiphy0_timer",
			      "csiphy1",
			      "csiphy1_timer",
			      "csiphy2",
			      "csiphy2_timer",
			      "csiphy3",
			      "csiphy3_timer",
			      "csiphy4",
			      "csiphy4_timer",
			      "csiphy5",
			      "csiphy5_timer",
			      "vfe0",
			      "vfe0_fast_ahb",
			      "vfe1",
			      "vfe1_fast_ahb",
			      "vfe2",
			      "vfe2_fast_ahb",
			      "vfe_lite",
			      "vfe_lite_ahb",
			      "vfe_lite_cphy_rx",
			      "vfe_lite_csid";

		interrupts = <GIC_SPI 464 IRQ_TYPE_EDGE_RISING>,
			     <GIC_SPI 466 IRQ_TYPE_EDGE_RISING>,
			     <GIC_SPI 640 IRQ_TYPE_EDGE_RISING>,
			     <GIC_SPI 468 IRQ_TYPE_EDGE_RISING>,
			     <GIC_SPI 359 IRQ_TYPE_EDGE_RISING>,
			     <GIC_SPI 477 IRQ_TYPE_EDGE_RISING>,
			     <GIC_SPI 478 IRQ_TYPE_EDGE_RISING>,
			     <GIC_SPI 479 IRQ_TYPE_EDGE_RISING>,
			     <GIC_SPI 448 IRQ_TYPE_EDGE_RISING>,
			     <GIC_SPI 122 IRQ_TYPE_EDGE_RISING>,
			     <GIC_SPI 89 IRQ_TYPE_EDGE_RISING>,
			     <GIC_SPI 465 IRQ_TYPE_EDGE_RISING>,
			     <GIC_SPI 467 IRQ_TYPE_EDGE_RISING>,
			     <GIC_SPI 641 IRQ_TYPE_EDGE_RISING>,
			     <GIC_SPI 469 IRQ_TYPE_EDGE_RISING>,
			     <GIC_SPI 360 IRQ_TYPE_EDGE_RISING>;
		interrupt-names = "csid0",
				  "csid1",
				  "csid2",
				  "csid_lite0",
				  "csid_lite1",
				  "csiphy0",
				  "csiphy1",
				  "csiphy2",
				  "csiphy3",
				  "csiphy4",
				  "csiphy5",
				  "vfe0",
				  "vfe1",
				  "vfe2",
				  "vfe_lite0",
				  "vfe_lite1";

		interconnects = <&gem_noc MASTER_APPSS_PROC QCOM_ICC_TAG_ACTIVE_ONLY
				 &config_noc SLAVE_CAMERA_CFG QCOM_ICC_TAG_ACTIVE_ONLY>,
				<&mmss_noc MASTER_CAMNOC_HF QCOM_ICC_TAG_ALWAYS
				 &mc_virt SLAVE_EBI1 QCOM_ICC_TAG_ALWAYS>;
		interconnect-names = "ahb",
				     "hf_0";

		iommus = <&apps_smmu 0x800 0x4e0>;

		power-domains = <&camcc IFE_0_GDSC>,
				<&camcc IFE_1_GDSC>,
				<&camcc IFE_2_GDSC>,
				<&camcc TITAN_TOP_GDSC>;
		power-domain-names = "ife0",
				     "ife1",
				     "ife2",
				     "top";

		status = "disabled";

		ports {
			#address-cells = <1>;
			#size-cells = <0>;

			port@0 {
				reg = <0>;
			};

			port@1 {
				reg = <1>;
			};

			port@2 {
				reg = <2>;
			};

			port@3 {
				reg = <3>;
			};

			port@4 {
				reg = <4>;
			};

			port@5 {
				reg = <5>;
			};
		};
	};
};

/* CSIPHY1 <- IMX355 (rear ultra wide), CCI0 master 0, MCLK1 */
&camss {
	iommus = <&apps_smmu 0x800 0x460>;
	vdda-phy-supply = <&pm8350_l5>;
	vdda-pll-supply = <&pm8350_l6>;
	status = "disabled";

	ports {
		#address-cells = <1>;
		#size-cells = <0>;

		port@1 {
			reg = <1>;

			csiphy1_ep: endpoint {
				data-lanes = <1 2>;
				bus-type = <MEDIA_BUS_TYPE_CSI2_DPHY>;
				remote-endpoint = <&imx355_ep>;
			};
		};
	};
};

&cci0 {
	status = "disabled";
};

&cci0_i2c0 {
	status = "disabled";

	/*
	 * Rear ultra-wide Sony IMX355. Wiring from the device's own vendor
	 * overlay (mondrian dtbo, fragment@142 = cam_cci0): CCI master 0,
	 * MCLK1, reset GPIO 24, and AVDD/DVDD/DOVDD all from CAMERA_ULTRA_AVDD
	 * (tlmm 6).
	 */
	camera@1a {
		compatible = "sony,imx355";
		reg = <0x1a>;

		power-domains = <&camcc TITAN_TOP_GDSC>;

		clocks = <&camcc CAM_CC_MCLK1_CLK>;
		assigned-clocks = <&camcc CAM_CC_MCLK1_CLK>;
		assigned-clock-rates = <19200000>;

		reset-gpios = <&tlmm 24 GPIO_ACTIVE_LOW>;
		pinctrl-names = "default", "suspend";
		pinctrl-0 = <&cam_mclk1_default &cam_reset2_default>;
		pinctrl-1 = <&cam_mclk1_suspend &cam_reset2_suspend>;

		avdd-supply = <&cam_ultra_avdd>;
		dvdd-supply = <&cam_ultra_avdd>;
		dovdd-supply = <&cam_ultra_avdd>;

		port {
			imx355_ep: endpoint {
				data-lanes = <1 2>;
				link-frequencies = /bits/ 64 <400000000>;
				remote-endpoint = <&csiphy1_ep>;
			};
		};
	};
};

&cci1 {
	status = "disabled";
};
